# MEC1322 register map
Vendor: Microchip Technology Inc.; Series: ARMCM4F; File version: 1.0
CPU: CM4 r1p0, little endian, MPU, FPU, 3 interrupt priority bits
Registers are 32-bit, read-write, reset 0x0 unless marked. A register's access mark holds for its fields unless they carry their own. Offsets are from the block's base; [hi:lo] are bit positions; 'fields as' and 'values as' point back to an identical list.

## KBC — The MEC1322 keyboard controller uses the EC to produce a superset of the features provided by the industry-standard 8042 keyboard controller. The 8042 Emulated Keyboard. Controller is a Host/EC Message Interface with hardware assists to emulate 8042 behavior and provide Legacy GATEA20 support.
Base 0x400F0400
0x00 RD_PORT60_DATA 8-bit read — EC_Host Data/Aux Register (Read) This 8-bit register is read-only. When read by the Host, the PCOBF and/or AUXOBF interrupts are cleared and the OBF flag in the status register is cleared.
0x00 WT_PORT60_DATA 8-bit write (alternate view of RD_PORT60_DATA) — Host_EC Data Register (Write) This 8-bit register is write-only. When written, the C/D bit in the Keyboard Status Read Register is cleared to '0', signifying data, and the IBF in the same register is set to '1'.
0x04 WT_PORT64_CMD 8-bit write — Host_EC Command Register (Write) This 8-bit register is write-only and is an alias of the register at offset 0h. When written, the C/D bit in the Keyboard Status Read Register is set to '1', signifying a command, and the IBF in the same register is set to '1'.
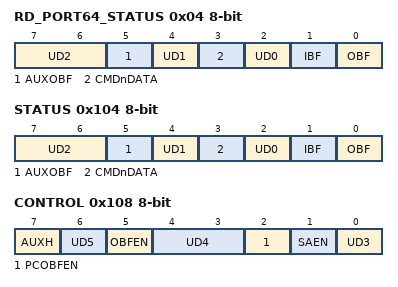
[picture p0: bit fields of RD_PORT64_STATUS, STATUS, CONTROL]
0x04 RD_PORT64_STATUS 8-bit (alternate view of WT_PORT64_CMD) — Keyboard Status Read Register
  [7:6] UD2 — UD2 User-defined data.
  [5] AUXOBF read — AUXOBF Auxiliary Output Buffer Full.
  [4] UD1 — UD1 User-defined data.
  [3] CMDnDATA read — C/D Command Data. This bit specifies whether the input data register contains data or a command ('0' = data, '1' = command).
  [2] UD0 — UD0 User-defined data.
  [1] IBF read — IBF Input Buffer Full.
  [0] OBF read — OBF Output Buffer Full.
0x100 HOST2EC_DATA 8-bit read — Host_EC Data/Cmd Register This register is an alias of the HOST_EC Data / CMD Register.
0x100 EC_DATA 8-bit write (alternate view of HOST2EC_DATA) — EC_Host Data Register
0x104 STATUS 8-bit — Keyboard Status Read Register
  fields as RD_PORT64_STATUS
0x108 CONTROL 8-bit — Keyboard Control Register
  [7] AUXH — AUXH AUX in Hardware. 1=AUXOBF of the Keyboard Status Read Register is set in hardware by a write to the EC AUX Data Register. 0=AUXOBF is not modified in hardware, but can be read and written by the EC using the EC-Only alias of the EC Keyboard Status Register
  [6] UD5 — UD5 User-defined data.
  [5] OBFEN — OBFEN When this bit is '1, the system interrupt signal KIRQ is driven by the bit PCOBF and MIRQ is driven by AUXOBF. When this bit is '0', KIRQ and MIRQ are driven low.
  [4:3] UD4 — UD4 User-defined data.
  [2] PCOBFEN — PCOBFEN 1= reflects the value written to the PCOBF Register, 0=PCOBF reflects the status of writes to the EC Data Register
  [1] SAEN — SAEN Software-assist enable. 1=This bit allows control of the GATEA20 signal via firmware 0=GATEA20 corresponds to either the last Host-initiated control of GATEA20 or the firmware write to the Keyboard Control Register or the EC AUX Data Register.
  [0] UD3 — UD3 User-defined data.
0x10C AUX_DATA 8-bit write — EC_Host Aux Register This 8-bit register is write-only. When written, the C/D in the Keyboard Status Read Register is cleared to '0', signifying data, and the IBF in the same register is set to '1'. When the Runtime Register at offset 0h is read by the Host, it functions as the EC_HOST Data / AUX Data Register.
0x114 PCOBF 8-bit — PCOBF Register: If enabled by the bit OBFEN, the bit PCOBF is gated onto KIRQ. The KIRQ signal is a system interrupt which signifies that the EC has written to the HOST2EC Data Register (EC-Only offset 0h).
0x330 ACTIVATE 8-bit — Activate Register [0:0] ACTIVATE 1=The 8042 Interface is powered and functional. 0=The 8042 Interface is powered down and inactive.
